VERSION ""

NS_ :

BS_:

BU_: PLUTUS PLUTUS_SLAVE CHAOS TELEMETRY LIGHTS_FRONT LIGHTS_REAR MOTOR_CONTROLLER DRIVER_CONTROLS_PEDAL DRIVER_CONTROLS_CENTER_CONSOLE SOLAR_MASTER_FRONT SOLAR_MASTER_REAR SENSOR_BOARD CHARGER DRIVER_CONTROLS_STEERING

BO_ 1 BPS_HEARTBEAT: 1 PLUTUS
 SG_ status : 0|8@1+ (1,0) [0|0] "" Vector__XXX

BO_ 19 BPS_HEARTBEAT_ACK_FROM_CHAOS: 1 CHAOS
 SG_ BPS_HEARTBEAT_FROM_CHAOS_ACK_STATUS : 0|8@1+ (1,0) [0|0] "" Vector__XXX

BO_ 21 BPS_HEARTBEAT_ACK_FROM_LIGHTS_FRONT: 1 LIGHTS_FRONT
 SG_ BPS_HEARTBEAT_FROM_LIGHTS_FRONT_ACK_STATUS : 0|8@1+ (1,0) [0|0] "" Vector__XXX

BO_ 18 BPS_HEARTBEAT_ACK_FROM_PLUTUS_SLAVE: 1 PLUTUS_SLAVE
 SG_ BPS_HEARTBEAT_FROM_PLUTUS_SLAVE_ACK_STATUS : 0|8@1+ (1,0) [0|0] "" Vector__XXX

BO_ 24 BPS_HEARTBEAT_ACK_FROM_DRIVER_CONTROLS_PEDAL: 1 DRIVER_CONTROLS_PEDAL
 SG_ BPS_HEARTBEAT_FROM_DRIVER_CONTROLS_PEDAL_ACK_STATUS : 0|8@1+ (1,0) [0|0] "" Vector__XXX

BO_ 35 POWER_DISTRIBUTION_FAULT: 1 CHAOS
 SG_ reason : 0|8@1+ (1,0) [0|0] "" Vector__XXX

BO_ 56 POWER_DISTRIBUTION_FAULT_ACK_FROM_DRIVER_CONTROLS_PEDAL: 1 DRIVER_CONTROLS_PEDAL
 SG_ POWER_DISTRIBUTION_FAULT_FROM_DRIVER_CONTROLS_PEDAL_ACK_STATUS : 0|8@1+ (1,0) [0|0] "" Vector__XXX

BO_ 67 BATTERY_RELAY_MAIN: 1 CHAOS
 SG_ relay_state : 0|8@1+ (1,0) [0|0] "" Vector__XXX

BO_ 81 BATTERY_RELAY_MAIN_ACK_FROM_PLUTUS: 1 PLUTUS
 SG_ BATTERY_RELAY_MAIN_FROM_PLUTUS_ACK_STATUS : 0|8@1+ (1,0) [0|0] "" Vector__XXX

BO_ 99 BATTERY_RELAY_SLAVE: 1 CHAOS
 SG_ relay_state : 0|8@1+ (1,0) [0|0] "" Vector__XXX

BO_ 114 BATTERY_RELAY_SLAVE_ACK_FROM_PLUTUS_SLAVE: 1 PLUTUS_SLAVE
 SG_ BATTERY_RELAY_SLAVE_FROM_PLUTUS_SLAVE_ACK_STATUS : 0|8@1+ (1,0) [0|0] "" Vector__XXX

BO_ 131 MOTOR_RELAY: 1 CHAOS
 SG_ relay_state : 0|8@1+ (1,0) [0|0] "" Vector__XXX

BO_ 151 MOTOR_RELAY_ACK_FROM_MOTOR_CONTROLLER: 1 MOTOR_CONTROLLER
 SG_ MOTOR_RELAY_FROM_MOTOR_CONTROLLER_ACK_STATUS : 0|8@1+ (1,0) [0|0] "" Vector__XXX

BO_ 163 SOLAR_RELAY_REAR: 1 CHAOS
 SG_ relay_state : 0|8@1+ (1,0) [0|0] "" Vector__XXX

BO_ 187 SOLAR_RELAY_REAR_ACK_FROM_SOLAR_MASTER_REAR: 1 SOLAR_MASTER_REAR
 SG_ SOLAR_RELAY_REAR_FROM_SOLAR_MASTER_REAR_ACK_STATUS : 0|8@1+ (1,0) [0|0] "" Vector__XXX

BO_ 195 SOLAR_RELAY_FRONT: 1 CHAOS
 SG_ relay_state : 0|8@1+ (1,0) [0|0] "" Vector__XXX

BO_ 218 SOLAR_RELAY_FRONT_ACK_FROM_SOLAR_MASTER_FRONT: 1 SOLAR_MASTER_FRONT
 SG_ SOLAR_RELAY_FRONT_FROM_SOLAR_MASTER_FRONT_ACK_STATUS : 0|8@1+ (1,0) [0|0] "" Vector__XXX

BO_ 232 POWER_STATE: 1 DRIVER_CONTROLS_PEDAL
 SG_ power_state : 0|8@1+ (1,0) [0|0] "" Vector__XXX

BO_ 243 POWER_STATE_ACK_FROM_CHAOS: 1 CHAOS
 SG_ POWER_STATE_FROM_CHAOS_ACK_STATUS : 0|8@1+ (1,0) [0|0] "" Vector__XXX

BO_ 259 POWERTRAIN_HEARTBEAT: 0 CHAOS

BO_ 273 POWERTRAIN_HEARTBEAT_ACK_FROM_PLUTUS: 1 PLUTUS
 SG_ POWERTRAIN_HEARTBEAT_FROM_PLUTUS_ACK_STATUS : 0|8@1+ (1,0) [0|0] "" Vector__XXX

BO_ 279 POWERTRAIN_HEARTBEAT_ACK_FROM_MOTOR_CONTROLLER: 1 MOTOR_CONTROLLER
 SG_ POWERTRAIN_HEARTBEAT_FROM_MOTOR_CONTROLLER_ACK_STATUS : 0|8@1+ (1,0) [0|0] "" Vector__XXX

BO_ 280 POWERTRAIN_HEARTBEAT_ACK_FROM_DRIVER_CONTROLS_PEDAL: 1 DRIVER_CONTROLS_PEDAL
 SG_ POWERTRAIN_HEARTBEAT_FROM_DRIVER_CONTROLS_PEDAL_ACK_STATUS : 0|8@1+ (1,0) [0|0] "" Vector__XXX

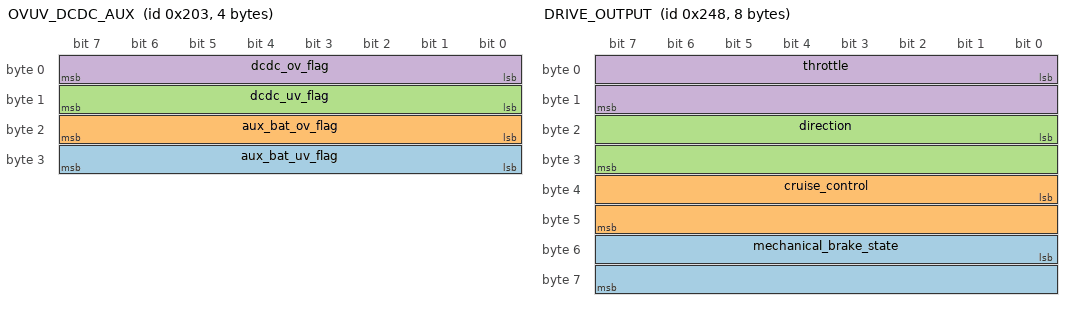
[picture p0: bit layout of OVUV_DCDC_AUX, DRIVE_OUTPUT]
BO_ 515 OVUV_DCDC_AUX: 4 CHAOS
 SG_ aux_bat_uv_flag : 24|8@1+ (1,0) [0|0] "" Vector__XXX
 SG_ aux_bat_ov_flag : 16|8@1+ (1,0) [0|0] "" Vector__XXX
 SG_ dcdc_uv_flag : 8|8@1+ (1,0) [0|0] "" Vector__XXX
 SG_ dcdc_ov_flag : 0|8@1+ (1,0) [0|0] "" Vector__XXX

BO_ 551 MC_ERROR_LIMITS: 4 MOTOR_CONTROLLER
 SG_ limits : 16|16@1+ (1,0) [0|0] "" Vector__XXX
 SG_ error_id : 0|16@1+ (1,0) [0|0] "" Vector__XXX

BO_ 584 DRIVE_OUTPUT: 8 DRIVER_CONTROLS_PEDAL
 SG_ mechanical_brake_state : 48|16@1- (1,0) [0|0] "" Vector__XXX
 SG_ cruise_control : 32|16@1- (1,0) [0|0] "" Vector__XXX
 SG_ direction : 16|16@1- (1,0) [0|0] "" Vector__XXX
 SG_ throttle : 0|16@1- (1,0) [0|0] "" Vector__XXX

BO_ 616 CRUISE_TARGET: 1 DRIVER_CONTROLS_PEDAL
 SG_ target_speed : 0|8@1- (1,0) [0|0] "" Vector__XXX

BO_ 643 FAN_CONTROL: 1 CHAOS
 SG_ state : 0|8@1+ (1,0) [0|0] "" Vector__XXX

BO_ 676 SET_MODULE_DISCHARGE: 2 TELEMETRY
 SG_ discharge : 8|8@1+ (1,0) [0|0] "" Vector__XXX
 SG_ module : 0|8@1+ (1,0) [0|0] "" Vector__XXX

BO_ 705 DISCHARGE_STATE: 8 PLUTUS
 SG_ discharge_bitset : 0|64@1+ (1,0) [0|0] "" Vector__XXX

BO_ 742 LIGHTS_SYNC: 0 LIGHTS_REAR

BO_ 776 LIGHTS_STATE: 2 DRIVER_CONTROLS_PEDAL
 SG_ light_state : 8|8@1+ (1,0) [0|0] "" Vector__XXX
 SG_ light_id : 0|8@1+ (1,0) [0|0] "" Vector__XXX

BO_ 808 HORN: 1 DRIVER_CONTROLS_PEDAL
 SG_ state : 0|8@1+ (1,0) [0|0] "" Vector__XXX

BO_ 845 CHARGER_CONN_STATE: 1 CHARGER
 SG_ is_connected : 0|8@1+ (1,0) [0|0] "" Vector__XXX

BO_ 867 CHARGER_SET_RELAY_STATE: 1 CHAOS
 SG_ state : 0|8@1+ (1,0) [0|0] "" Vector__XXX

BO_ 910 STEERING_EVENT: 4 DRIVER_CONTROLS_STEERING
 SG_ data : 16|16@1+ (1,0) [0|0] "" Vector__XXX
 SG_ event_id : 0|16@1+ (1,0) [0|0] "" Vector__XXX

BO_ 937 CENTER_CONSOLE_EVENT: 4 DRIVER_CONTROLS_CENTER_CONSOLE
 SG_ data : 16|16@1+ (1,0) [0|0] "" Vector__XXX
 SG_ event_id : 0|16@1+ (1,0) [0|0] "" Vector__XXX

BO_ 968 MOTOR_CONTROLLER_RESET: 1 DRIVER_CONTROLS_PEDAL
 SG_ motor_controller_index : 0|8@1+ (1,0) [0|0] "" Vector__XXX

BO_ 993 BATTERY_SOC: 0 PLUTUS

BO_ 1025 BATTERY_VT: 6 PLUTUS
 SG_ MODULE_TEMP_035 m35 : 32|16@1+ (1,0) [0|0] "" Vector__XXX
 SG_ MODULE_TEMP_034 m34 : 32|16@1+ (1,0) [0|0] "" Vector__XXX
 SG_ MODULE_TEMP_033 m33 : 32|16@1+ (1,0) [0|0] "" Vector__XXX
 SG_ MODULE_TEMP_032 m32 : 32|16@1+ (1,0) [0|0] "" Vector__XXX
 SG_ MODULE_TEMP_031 m31 : 32|16@1+ (1,0) [0|0] "" Vector__XXX
 SG_ MODULE_TEMP_030 m30 : 32|16@1+ (1,0) [0|0] "" Vector__XXX
 SG_ MODULE_TEMP_029 m29 : 32|16@1+ (1,0) [0|0] "" Vector__XXX
 SG_ MODULE_TEMP_028 m28 : 32|16@1+ (1,0) [0|0] "" Vector__XXX
 SG_ MODULE_TEMP_027 m27 : 32|16@1+ (1,0) [0|0] "" Vector__XXX
 SG_ MODULE_TEMP_026 m26 : 32|16@1+ (1,0) [0|0] "" Vector__XXX
 SG_ MODULE_TEMP_025 m25 : 32|16@1+ (1,0) [0|0] "" Vector__XXX
 SG_ MODULE_TEMP_024 m24 : 32|16@1+ (1,0) [0|0] "" Vector__XXX
 SG_ MODULE_TEMP_023 m23 : 32|16@1+ (1,0) [0|0] "" Vector__XXX
 SG_ MODULE_TEMP_022 m22 : 32|16@1+ (1,0) [0|0] "" Vector__XXX
 SG_ MODULE_TEMP_021 m21 : 32|16@1+ (1,0) [0|0] "" Vector__XXX
 SG_ MODULE_TEMP_020 m20 : 32|16@1+ (1,0) [0|0] "" Vector__XXX
 SG_ MODULE_TEMP_019 m19 : 32|16@1+ (1,0) [0|0] "" Vector__XXX
 SG_ MODULE_TEMP_018 m18 : 32|16@1+ (1,0) [0|0] "" Vector__XXX
 SG_ MODULE_TEMP_017 m17 : 32|16@1+ (1,0) [0|0] "" Vector__XXX
 SG_ MODULE_TEMP_016 m16 : 32|16@1+ (1,0) [0|0] "" Vector__XXX
 SG_ MODULE_TEMP_015 m15 : 32|16@1+ (1,0) [0|0] "" Vector__XXX
 SG_ MODULE_TEMP_014 m14 : 32|16@1+ (1,0) [0|0] "" Vector__XXX
 SG_ MODULE_TEMP_013 m13 : 32|16@1+ (1,0) [0|0] "" Vector__XXX
 SG_ MODULE_TEMP_012 m12 : 32|16@1+ (1,0) [0|0] "" Vector__XXX
 SG_ MODULE_TEMP_011 m11 : 32|16@1+ (1,0) [0|0] "" Vector__XXX
 SG_ MODULE_TEMP_010 m10 : 32|16@1+ (1,0) [0|0] "" Vector__XXX
 SG_ MODULE_TEMP_009 m9 : 32|16@1+ (1,0) [0|0] "" Vector__XXX
 SG_ MODULE_TEMP_008 m8 : 32|16@1+ (1,0) [0|0] "" Vector__XXX
 SG_ MODULE_TEMP_007 m7 : 32|16@1+ (1,0) [0|0] "" Vector__XXX
 SG_ MODULE_TEMP_006 m6 : 32|16@1+ (1,0) [0|0] "" Vector__XXX
 SG_ MODULE_TEMP_005 m5 : 32|16@1+ (1,0) [0|0] "" Vector__XXX
 SG_ MODULE_TEMP_004 m4 : 32|16@1+ (1,0) [0|0] "" Vector__XXX
 SG_ MODULE_TEMP_003 m3 : 32|16@1+ (1,0) [0|0] "" Vector__XXX
 SG_ MODULE_TEMP_002 m2 : 32|16@1+ (1,0) [0|0] "" Vector__XXX
 SG_ MODULE_TEMP_001 m1 : 32|16@1+ (1,0) [0|0] "" Vector__XXX
 SG_ MODULE_TEMP_000 m0 : 32|16@1+ (1,0) [0|0] "" Vector__XXX
 SG_ MODULE_VOLTAGE_035 m35 : 16|16@1+ (1,0) [0|0] "" Vector__XXX
 SG_ MODULE_VOLTAGE_034 m34 : 16|16@1+ (1,0) [0|0] "" Vector__XXX
 SG_ MODULE_VOLTAGE_033 m33 : 16|16@1+ (1,0) [0|0] "" Vector__XXX
 SG_ MODULE_VOLTAGE_032 m32 : 16|16@1+ (1,0) [0|0] "" Vector__XXX
 SG_ MODULE_VOLTAGE_031 m31 : 16|16@1+ (1,0) [0|0] "" Vector__XXX
 SG_ MODULE_VOLTAGE_030 m30 : 16|16@1+ (1,0) [0|0] "" Vector__XXX
 SG_ MODULE_VOLTAGE_029 m29 : 16|16@1+ (1,0) [0|0] "" Vector__XXX
 SG_ MODULE_VOLTAGE_028 m28 : 16|16@1+ (1,0) [0|0] "" Vector__XXX
 SG_ MODULE_VOLTAGE_027 m27 : 16|16@1+ (1,0) [0|0] "" Vector__XXX
 SG_ MODULE_VOLTAGE_026 m26 : 16|16@1+ (1,0) [0|0] "" Vector__XXX
 SG_ MODULE_VOLTAGE_025 m25 : 16|16@1+ (1,0) [0|0] "" Vector__XXX
 SG_ MODULE_VOLTAGE_024 m24 : 16|16@1+ (1,0) [0|0] "" Vector__XXX
 SG_ MODULE_VOLTAGE_023 m23 : 16|16@1+ (1,0) [0|0] "" Vector__XXX
 SG_ MODULE_VOLTAGE_022 m22 : 16|16@1+ (1,0) [0|0] "" Vector__XXX
 SG_ MODULE_VOLTAGE_021 m21 : 16|16@1+ (1,0) [0|0] "" Vector__XXX
 SG_ MODULE_VOLTAGE_020 m20 : 16|16@1+ (1,0) [0|0] "" Vector__XXX
 SG_ MODULE_VOLTAGE_019 m19 : 16|16@1+ (1,0) [0|0] "" Vector__XXX
 SG_ MODULE_VOLTAGE_018 m18 : 16|16@1+ (1,0) [0|0] "" Vector__XXX
 SG_ MODULE_VOLTAGE_017 m17 : 16|16@1+ (1,0) [0|0] "" Vector__XXX
 SG_ MODULE_VOLTAGE_016 m16 : 16|16@1+ (1,0) [0|0] "" Vector__XXX
 SG_ MODULE_VOLTAGE_015 m15 : 16|16@1+ (1,0) [0|0] "" Vector__XXX
 SG_ MODULE_VOLTAGE_014 m14 : 16|16@1+ (1,0) [0|0] "" Vector__XXX
 SG_ MODULE_VOLTAGE_013 m13 : 16|16@1+ (1,0) [0|0] "" Vector__XXX
 SG_ MODULE_VOLTAGE_012 m12 : 16|16@1+ (1,0) [0|0] "" Vector__XXX
 SG_ MODULE_VOLTAGE_011 m11 : 16|16@1+ (1,0) [0|0] "" Vector__XXX
 SG_ MODULE_VOLTAGE_010 m10 : 16|16@1+ (1,0) [0|0] "" Vector__XXX
 SG_ MODULE_VOLTAGE_009 m9 : 16|16@1+ (1,0) [0|0] "" Vector__XXX
 SG_ MODULE_VOLTAGE_008 m8 : 16|16@1+ (1,0) [0|0] "" Vector__XXX
 SG_ MODULE_VOLTAGE_007 m7 : 16|16@1+ (1,0) [0|0] "" Vector__XXX
 SG_ MODULE_VOLTAGE_006 m6 : 16|16@1+ (1,0) [0|0] "" Vector__XXX
 SG_ MODULE_VOLTAGE_005 m5 : 16|16@1+ (1,0) [0|0] "" Vector__XXX
 SG_ MODULE_VOLTAGE_004 m4 : 16|16@1+ (1,0) [0|0] "" Vector__XXX
 SG_ MODULE_VOLTAGE_003 m3 : 16|16@1+ (1,0) [0|0] "" Vector__XXX
 SG_ MODULE_VOLTAGE_002 m2 : 16|16@1+ (1,0) [0|0] "" Vector__XXX
 SG_ MODULE_VOLTAGE_001 m1 : 16|16@1+ (1,0) [0|0] "" Vector__XXX
 SG_ MODULE_VOLTAGE_000 m0 : 16|16@1+ (1,0) [0|0] "" Vector__XXX
 SG_ BATTERY_VT_INDEX M : 0|16@1+ (1,0) [0|0] "" Vector__XXX

BO_ 1057 BATTERY_AGGREGATE_VC: 8 PLUTUS
 SG_ current : 32|32@1- (1,0) [0|0] "" Vector__XXX
 SG_ voltage : 0|32@1+ (1,0) [0|0] "" Vector__XXX

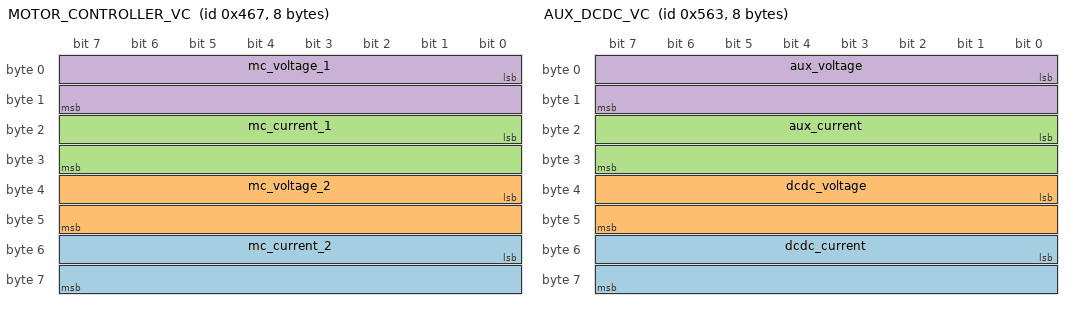
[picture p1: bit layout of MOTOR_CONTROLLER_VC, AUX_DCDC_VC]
BO_ 1127 MOTOR_CONTROLLER_VC: 8 MOTOR_CONTROLLER
 SG_ mc_current_2 : 48|16@1+ (1,0) [0|0] "" Vector__XXX
 SG_ mc_voltage_2 : 32|16@1+ (1,0) [0|0] "" Vector__XXX
 SG_ mc_current_1 : 16|16@1+ (1,0) [0|0] "" Vector__XXX
 SG_ mc_voltage_1 : 0|16@1+ (1,0) [0|0] "" Vector__XXX

BO_ 1159 MOTOR_VELOCITY: 4 MOTOR_CONTROLLER
 SG_ vehicle_velocity_right : 16|16@1- (1,0) [0|0] "" Vector__XXX
 SG_ vehicle_velocity_left : 0|16@1- (1,0) [0|0] "" Vector__XXX

BO_ 1191 MOTOR_DEBUG: 8 MOTOR_CONTROLLER
 SG_ data : 0|64@1+ (1,0) [0|0] "" Vector__XXX

BO_ 1223 MOTOR_TEMPS: 8 MOTOR_CONTROLLER
 SG_ motor_temp_r : 32|32@1+ (1,0) [0|0] "" Vector__XXX
 SG_ motor_temp_l : 0|32@1+ (1,0) [0|0] "" Vector__XXX

BO_ 1255 MOTOR_AMP_HR: 8 MOTOR_CONTROLLER
 SG_ motor_amp_hr_r : 32|32@1+ (1,0) [0|0] "" Vector__XXX
 SG_ motor_amp_hr_l : 0|32@1+ (1,0) [0|0] "" Vector__XXX

BO_ 1287 ODOMETER: 4 MOTOR_CONTROLLER
 SG_ odometer_val : 0|32@1+ (1,0) [0|0] "" Vector__XXX

BO_ 1379 AUX_DCDC_VC: 8 CHAOS
 SG_ dcdc_current : 48|16@1+ (1,0) [0|0] "" Vector__XXX
 SG_ dcdc_voltage : 32|16@1+ (1,0) [0|0] "" Vector__XXX
 SG_ aux_current : 16|16@1+ (1,0) [0|0] "" Vector__XXX
 SG_ aux_voltage : 0|16@1+ (1,0) [0|0] "" Vector__XXX

BO_ 1411 DCDC_TEMPS: 4 CHAOS
 SG_ temp_2 : 16|16@1+ (1,0) [0|0] "" Vector__XXX
 SG_ temp_1 : 0|16@1+ (1,0) [0|0] "" Vector__XXX

BO_ 1450 SOLAR_DATA_FRONT: 8 SOLAR_MASTER_FRONT
 SG_ MODULE_TEMP_005 m5 : 48|16@1+ (1,0) [0|0] "" Vector__XXX
 SG_ MODULE_TEMP_004 m4 : 48|16@1+ (1,0) [0|0] "" Vector__XXX
 SG_ MODULE_TEMP_003 m3 : 48|16@1+ (1,0) [0|0] "" Vector__XXX
 SG_ MODULE_TEMP_002 m2 : 48|16@1+ (1,0) [0|0] "" Vector__XXX
 SG_ MODULE_TEMP_001 m1 : 48|16@1+ (1,0) [0|0] "" Vector__XXX
 SG_ MODULE_TEMP_000 m0 : 48|16@1+ (1,0) [0|0] "" Vector__XXX
 SG_ MODULE_CURRENT_005 m5 : 32|16@1+ (1,0) [0|0] "" Vector__XXX
 SG_ MODULE_CURRENT_004 m4 : 32|16@1+ (1,0) [0|0] "" Vector__XXX
 SG_ MODULE_CURRENT_003 m3 : 32|16@1+ (1,0) [0|0] "" Vector__XXX
 SG_ MODULE_CURRENT_002 m2 : 32|16@1+ (1,0) [0|0] "" Vector__XXX
 SG_ MODULE_CURRENT_001 m1 : 32|16@1+ (1,0) [0|0] "" Vector__XXX
 SG_ MODULE_CURRENT_000 m0 : 32|16@1+ (1,0) [0|0] "" Vector__XXX
 SG_ MODULE_VOLTAGE_005 m5 : 16|16@1+ (1,0) [0|0] "" Vector__XXX
 SG_ MODULE_VOLTAGE_004 m4 : 16|16@1+ (1,0) [0|0] "" Vector__XXX
 SG_ MODULE_VOLTAGE_003 m3 : 16|16@1+ (1,0) [0|0] "" Vector__XXX
 SG_ MODULE_VOLTAGE_002 m2 : 16|16@1+ (1,0) [0|0] "" Vector__XXX
 SG_ MODULE_VOLTAGE_001 m1 : 16|16@1+ (1,0) [0|0] "" Vector__XXX
 SG_ MODULE_VOLTAGE_000 m0 : 16|16@1+ (1,0) [0|0] "" Vector__XXX
 SG_ SOLAR_SLAVE_INDEX M : 0|16@1+ (1,0) [0|0] "" Vector__XXX

BO_ 1483 SOLAR_DATA_REAR: 8 SOLAR_MASTER_REAR
 SG_ MODULE_TEMP_005 m5 : 48|16@1+ (1,0) [0|0] "" Vector__XXX
 SG_ MODULE_TEMP_004 m4 : 48|16@1+ (1,0) [0|0] "" Vector__XXX
 SG_ MODULE_TEMP_003 m3 : 48|16@1+ (1,0) [0|0] "" Vector__XXX
 SG_ MODULE_TEMP_002 m2 : 48|16@1+ (1,0) [0|0] "" Vector__XXX
 SG_ MODULE_TEMP_001 m1 : 48|16@1+ (1,0) [0|0] "" Vector__XXX
 SG_ MODULE_TEMP_000 m0 : 48|16@1+ (1,0) [0|0] "" Vector__XXX
 SG_ MODULE_CURRENT_005 m5 : 32|16@1+ (1,0) [0|0] "" Vector__XXX
 SG_ MODULE_CURRENT_004 m4 : 32|16@1+ (1,0) [0|0] "" Vector__XXX
 SG_ MODULE_CURRENT_003 m3 : 32|16@1+ (1,0) [0|0] "" Vector__XXX
 SG_ MODULE_CURRENT_002 m2 : 32|16@1+ (1,0) [0|0] "" Vector__XXX
 SG_ MODULE_CURRENT_001 m1 : 32|16@1+ (1,0) [0|0] "" Vector__XXX
 SG_ MODULE_CURRENT_000 m0 : 32|16@1+ (1,0) [0|0] "" Vector__XXX
 SG_ MODULE_VOLTAGE_005 m5 : 16|16@1+ (1,0) [0|0] "" Vector__XXX
 SG_ MODULE_VOLTAGE_004 m4 : 16|16@1+ (1,0) [0|0] "" Vector__XXX
 SG_ MODULE_VOLTAGE_003 m3 : 16|16@1+ (1,0) [0|0] "" Vector__XXX
 SG_ MODULE_VOLTAGE_002 m2 : 16|16@1+ (1,0) [0|0] "" Vector__XXX
 SG_ MODULE_VOLTAGE_001 m1 : 16|16@1+ (1,0) [0|0] "" Vector__XXX
 SG_ MODULE_VOLTAGE_000 m0 : 16|16@1+ (1,0) [0|0] "" Vector__XXX
 SG_ SOLAR_SLAVE_INDEX M : 0|16@1+ (1,0) [0|0] "" Vector__XXX

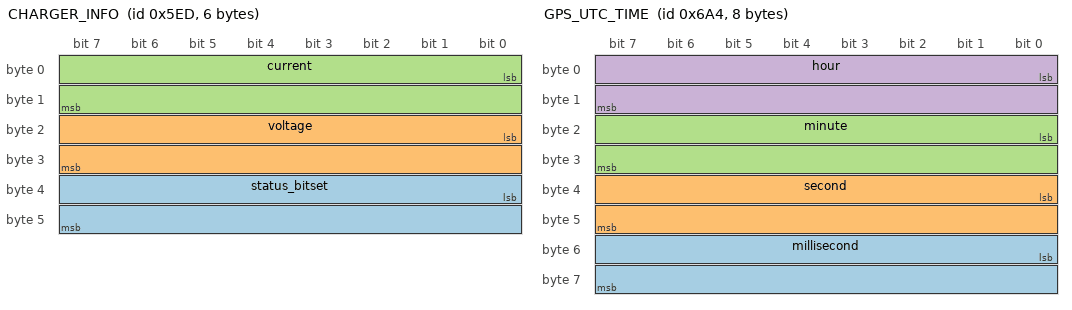
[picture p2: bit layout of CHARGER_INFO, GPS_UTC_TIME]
BO_ 1517 CHARGER_INFO: 6 CHARGER
 SG_ status_bitset : 32|16@1+ (1,0) [0|0] "" Vector__XXX
 SG_ voltage : 16|16@1+ (1,0) [0|0] "" Vector__XXX
 SG_ current : 0|16@1+ (1,0) [0|0] "" Vector__XXX

BO_ 1644 LINEAR_ACCELERATION: 0 SENSOR_BOARD

BO_ 1676 ANGULAR_ROTATION: 0 SENSOR_BOARD

BO_ 1700 GPS_UTC_TIME: 8 TELEMETRY
 SG_ millisecond : 48|16@1+ (1,0) [0|0] "" Vector__XXX
 SG_ second : 32|16@1+ (1,0) [0|0] "" Vector__XXX
 SG_ minute : 16|16@1+ (1,0) [0|0] "" Vector__XXX
 SG_ hour : 0|16@1+ (1,0) [0|0] "" Vector__XXX

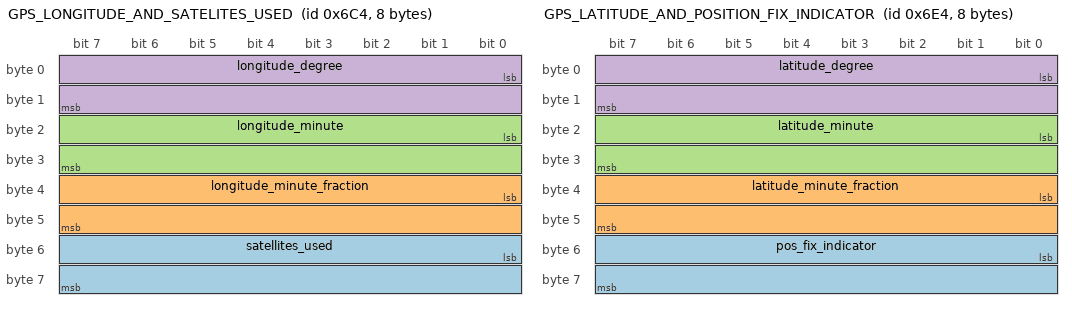
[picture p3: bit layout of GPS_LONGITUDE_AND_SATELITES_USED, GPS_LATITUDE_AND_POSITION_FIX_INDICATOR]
BO_ 1732 GPS_LONGITUDE_AND_SATELITES_USED: 8 TELEMETRY
 SG_ satellites_used : 48|16@1+ (1,0) [0|0] "" Vector__XXX
 SG_ longitude_minute_fraction : 32|16@1+ (1,0) [0|0] "" Vector__XXX
 SG_ longitude_minute : 16|16@1+ (1,0) [0|0] "" Vector__XXX
 SG_ longitude_degree : 0|16@1+ (1,0) [0|0] "" Vector__XXX

BO_ 1764 GPS_LATITUDE_AND_POSITION_FIX_INDICATOR: 8 TELEMETRY
 SG_ pos_fix_indicator : 48|16@1+ (1,0) [0|0] "" Vector__XXX
 SG_ latitude_minute_fraction : 32|16@1+ (1,0) [0|0] "" Vector__XXX
 SG_ latitude_minute : 16|16@1+ (1,0) [0|0] "" Vector__XXX
 SG_ latitude_degree : 0|16@1+ (1,0) [0|0] "" Vector__XXX

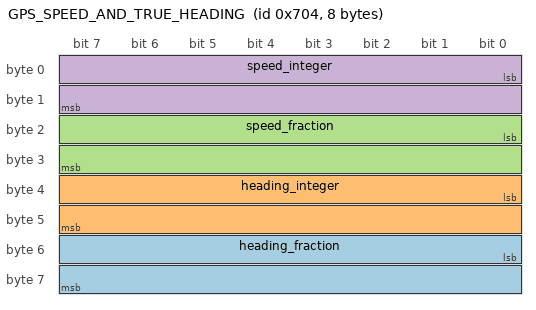
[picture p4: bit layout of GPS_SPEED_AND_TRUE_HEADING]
BO_ 1796 GPS_SPEED_AND_TRUE_HEADING: 8 TELEMETRY
 SG_ heading_fraction : 48|16@1+ (1,0) [0|0] "" Vector__XXX
 SG_ heading_integer : 32|16@1+ (1,0) [0|0] "" Vector__XXX
 SG_ speed_fraction : 16|16@1+ (1,0) [0|0] "" Vector__XXX
 SG_ speed_integer : 0|16@1+ (1,0) [0|0] "" Vector__XXX

CM_ BU_ PLUTUS "Device ID: 0x1";
CM_ BU_ PLUTUS_SLAVE "Device ID: 0x2";
CM_ BU_ CHAOS "Device ID: 0x3";
CM_ BU_ TELEMETRY "Device ID: 0x4";
CM_ BU_ LIGHTS_FRONT "Device ID: 0x5";
CM_ BU_ LIGHTS_REAR "Device ID: 0x6";
CM_ BU_ MOTOR_CONTROLLER "Device ID: 0x7";
CM_ BU_ DRIVER_CONTROLS_PEDAL "Device ID: 0x8";
CM_ BU_ DRIVER_CONTROLS_CENTER_CONSOLE "Device ID: 0x9";
CM_ BU_ SOLAR_MASTER_FRONT "Device ID: 0xa";
CM_ BU_ SOLAR_MASTER_REAR "Device ID: 0xb";
CM_ BU_ SENSOR_BOARD "Device ID: 0xc";
CM_ BU_ CHARGER "Device ID: 0xd";
CM_ BU_ DRIVER_CONTROLS_STEERING "Device ID: 0xe";
